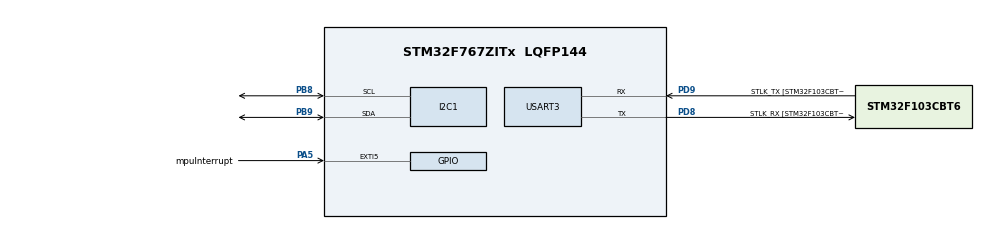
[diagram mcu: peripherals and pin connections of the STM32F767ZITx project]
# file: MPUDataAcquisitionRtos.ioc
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FREERTOS.Queues01=rxQueue,5,uint8_t,0,Static,rxQueueBuffer,rxQueueControlBlock;txQueue,13,uint16_t,0,Static,myQueue02Buffer,myQueue02ControlBlock
FREERTOS.Tasks01=mainTask,24,128,StartDefaultTask,Default,NULL,Static,mainTaskBuffer,mainTaskControlBlock;mpuTask,24,128,StartTask02,Default,NULL,Static,mpuTaskBuffer,mpuTaskControlBlock
I2C1.Analog_Filter=I2C_ANALOGFILTER_DISABLE
I2C1.Timing=0x00B0DBFF
Mcu.Family=STM32F7
Mcu.Name=STM32F767ZITx
Mcu.Package=LQFP144
NVIC.EXTI9_5_IRQn=true\:5\:0\:false\:false\:true\:true\:true\:true
NVIC.PriorityGroup=NVIC_PRIORITYGROUP_4
NVIC.TIM7_IRQn=true\:0\:0\:false\:false\:true\:false\:false\:true
NVIC.TimeBase=TIM7_IRQn
NVIC.TimeBaseIP=TIM7
NVIC.USART3_IRQn=true\:5\:0\:false\:false\:true\:true\:true\:true
PA13.GPIO_Label=TMS
PA13.Mode=Serial_Wire
PA13.Signal=SYS_JTMS-SWDIO
PA14.GPIO_Label=TCK
PA14.Mode=Serial_Wire
PA14.Signal=SYS_JTCK-SWCLK
PA5.GPIO_Label=mpuInterrupt
PA5.Signal=GPXTI5
PB8.Mode=I2C
PB8.Signal=I2C1_SCL
PB9.Mode=I2C
PB9.Signal=I2C1_SDA
PC14/OSC32_IN.Mode=LSE-External-Oscillator
PC14/OSC32_IN.Signal=RCC_OSC32_IN
PC15/OSC32_OUT.Mode=LSE-External-Oscillator
PC15/OSC32_OUT.Signal=RCC_OSC32_OUT
PD8.GPIO_Label=STLK_RX [STM32F103CBT6_PA3]
PD8.Mode=Asynchronous
PD8.Signal=USART3_TX
PD9.GPIO_Label=STLK_TX [STM32F103CBT6_PA2]
PD9.Mode=Asynchronous
PD9.Signal=USART3_RX
PH0/OSC_IN.GPIO_Label=MCO [STM32F103CBT6_PA8]
PH0/OSC_IN.Mode=HSE-External-Clock-Source
PH0/OSC_IN.Signal=RCC_OSC_IN
PH1/OSC_OUT.Mode=HSE-External-Clock-Source
PH1/OSC_OUT.Signal=RCC_OSC_OUT
ProjectManager.HeapSize=0x200
ProjectManager.StackSize=0x400
ProjectManager.TargetToolchain=STM32CubeIDE
RCC.48MHZClocksFreq_Value=24000000
RCC.AHBFreq_Value=96000000
RCC.APB1CLKDivider=RCC_HCLK_DIV2
RCC.APB1Freq_Value=48000000
RCC.APB1TimFreq_Value=96000000
RCC.APB2Freq_Value=96000000
RCC.APB2TimFreq_Value=96000000
RCC.CortexFreq_Value=96000000
RCC.HCLKFreq_Value=96000000
RCC.HSE_VALUE=8000000
RCC.HSI_VALUE=16000000
RCC.PLLM=4
RCC.PLLMUL=RCC_PLL_MUL9
RCC.PLLN=96
RCC.PLLQ=4
RCC.PLLSourceVirtual=RCC_PLLSOURCE_HSE
RCC.PRESCALERUSB=RCC_USBCLKSOURCE_PLL_DIV1_5
RCC.SYSCLKFreq_VALUE=96000000
RCC.SYSCLKSource=RCC_SYSCLKSOURCE_PLLCLK
RCC.SYSCLKSourceVirtual=RCC_SYSCLKSOURCE_PLLCLK
RCC.USBFreq_Value=48000000
RCC.VCOOutputFreq_Value=192000000
USART3.VirtualMode-Asynchronous=VM_ASYNC
VP_FREERTOS_VS_CMSIS_V2.Mode=CMSIS_V2
VP_SYS_VS_tim7.Mode=TIM7
board=NUCLEO-F767ZI

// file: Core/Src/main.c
/* USER CODE BEGIN Header */
/**
  ******************************************************************************
  * @file           : main.c
  * @brief          : Main program body
  ******************************************************************************
  * @attention
  *
  * <h2><center>&copy; Copyright (c) 2020 STMicroelectronics.
  * All rights reserved.</center></h2>
  *
  * This software component is licensed by ST under BSD 3-Clause license,
  * the "License"; You may not use this file except in compliance with the
  * License. You may obtain a copy of the License at:
  *                        opensource.org/licenses/BSD-3-Clause
  *
  ******************************************************************************
  */
/* USER CODE END Header */

#include "main.h"
#include "cmsis_os.h"
#include "i2c.h"
#include "usart.h"
#include "gpio.h"

void SystemClock_Config(void);
void MX_FREERTOS_Init(void);

int main(void)
{

  /* MCU Configuration--------------------------------------------------------*/

  /* Reset of all peripherals, Initializes the Flash interface and the Systick. */
  HAL_Init();

  /* Configure the system clock */
  SystemClock_Config();

  /* Initialize all configured peripherals */
  MX_GPIO_Init();
  MX_USART3_UART_Init();
  MX_I2C1_Init();

  /* Init scheduler */
  osKernelInitialize();  /* Call init function for freertos objects (in freertos.c) */
  MX_FREERTOS_Init();
  /* Start scheduler */
  osKernelStart();

  /* We should never get here as control is now taken by the scheduler */
  /* Infinite loop */
  while (1)
  {

  }
}

void SystemClock_Config(void)
{
  LL_FLASH_SetLatency(LL_FLASH_LATENCY_3);

  if(LL_FLASH_GetLatency() != LL_FLASH_LATENCY_3)
  {
  Error_Handler();
  }
  LL_PWR_SetRegulVoltageScaling(LL_PWR_REGU_VOLTAGE_SCALE3);
  LL_PWR_EnableOverDriveMode();
  LL_RCC_HSE_EnableBypass();
  LL_RCC_HSE_Enable();

   /* Wait till HSE is ready */
  while(LL_RCC_HSE_IsReady() != 1)
  {

  }
  LL_RCC_PLL_ConfigDomain_SYS(LL_RCC_PLLSOURCE_HSE, LL_RCC_PLLM_DIV_4, 96, LL_RCC_PLLP_DIV_2);
  LL_RCC_PLL_Enable();

   /* Wait till PLL is ready */
  while(LL_RCC_PLL_IsReady() != 1)
  {

  }
  LL_RCC_SetAHBPrescaler(LL_RCC_SYSCLK_DIV_1);
  LL_RCC_SetAPB1Prescaler(LL_RCC_APB1_DIV_2);
  LL_RCC_SetAPB2Prescaler(LL_RCC_APB2_DIV_1);
  LL_RCC_SetSysClkSource(LL_RCC_SYS_CLKSOURCE_PLL);

   /* Wait till System clock is ready */
  while(LL_RCC_GetSysClkSource() != LL_RCC_SYS_CLKSOURCE_STATUS_PLL)
  {

  }
  LL_SetSystemCoreClock(96000000);

   /* Update the time base */
  if (HAL_InitTick (TICK_INT_PRIORITY) != HAL_OK)
  {
    Error_Handler();
  };
  LL_RCC_SetUSARTClockSource(LL_RCC_USART3_CLKSOURCE_PCLK1);
  LL_RCC_SetI2CClockSource(LL_RCC_I2C1_CLKSOURCE_PCLK1);
}

 /**
  * @brief  Period elapsed callback in non blocking mode
  * @note   This function is called  when TIM7 interrupt took place, inside
  * HAL_TIM_IRQHandler(). It makes a direct call to HAL_IncTick() to increment
  * a global variable "uwTick" used as application time base.
  * @param  htim : TIM handle
  * @retval None
  */
void HAL_TIM_PeriodElapsedCallback(TIM_HandleTypeDef *htim)
{
  if (htim->Instance == TIM7) {
    HAL_IncTick();
  }
}

void Error_Handler(void)
{
}

/************************ (C) COPYRIGHT STMicroelectronics *****END OF FILE****/

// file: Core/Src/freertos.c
/* USER CODE BEGIN Header */
/**
  ******************************************************************************
  * File Name          : freertos.c
  * Description        : Code for freertos applications
  ******************************************************************************
  * @attention
  *
  * <h2><center>&copy; Copyright (c) 2020 STMicroelectronics.
  * All rights reserved.</center></h2>
  *
  * This software component is licensed by ST under Ultimate Liberty license
  * SLA0044, the "License"; You may not use this file except in compliance with
  * the License. You may obtain a copy of the License at:
  *                             www.st.com/SLA0044
  *
  ******************************************************************************
  */
/* USER CODE END Header */

#include "FreeRTOS.h"
#include "task.h"
#include "main.h"
#include "cmsis_os.h"

typedef StaticTask_t osStaticThreadDef_t;
typedef StaticQueue_t osStaticMessageQDef_t;

/* Definitions for mainTask */
osThreadId_t mainTaskHandle;
uint32_t mainTaskBuffer[ 128 ];
osStaticThreadDef_t mainTaskControlBlock;
const osThreadAttr_t mainTask_attributes = {
  .name = "mainTask",
  .stack_mem = &mainTaskBuffer[0],
  .stack_size = sizeof(mainTaskBuffer),
  .cb_mem = &mainTaskControlBlock,
  .cb_size = sizeof(mainTaskControlBlock),
  .priority = (osPriority_t) osPriorityNormal,
};
/* Definitions for mpuTask */
osThreadId_t mpuTaskHandle;
uint32_t mpuTaskBuffer[ 128 ];
osStaticThreadDef_t mpuTaskControlBlock;
const osThreadAttr_t mpuTask_attributes = {
  .name = "mpuTask",
  .stack_mem = &mpuTaskBuffer[0],
  .stack_size = sizeof(mpuTaskBuffer),
  .cb_mem = &mpuTaskControlBlock,
  .cb_size = sizeof(mpuTaskControlBlock),
  .priority = (osPriority_t) osPriorityNormal,
};
/* Definitions for rxQueue */
osMessageQueueId_t rxQueueHandle;
uint8_t rxQueueBuffer[ 5 * sizeof( uint8_t ) ];
osStaticMessageQDef_t rxQueueControlBlock;
const osMessageQueueAttr_t rxQueue_attributes = {
  .name = "rxQueue",
  .cb_mem = &rxQueueControlBlock,
  .cb_size = sizeof(rxQueueControlBlock),
  .mq_mem = &rxQueueBuffer,
  .mq_size = sizeof(rxQueueBuffer)
};
/* Definitions for txQueue */
osMessageQueueId_t txQueueHandle;
uint8_t myQueue02Buffer[ 13 * sizeof( uint16_t ) ];
osStaticMessageQDef_t myQueue02ControlBlock;
const osMessageQueueAttr_t txQueue_attributes = {
  .name = "txQueue",
  .cb_mem = &myQueue02ControlBlock,
  .cb_size = sizeof(myQueue02ControlBlock),
  .mq_mem = &myQueue02Buffer,
  .mq_size = sizeof(myQueue02Buffer)
};

void StartDefaultTask(void *argument);
void StartMpuTask(void *argument);

void MX_FREERTOS_Init(void); /* (MISRA C 2004 rule 8.1) */

void MX_FREERTOS_Init(void) {

  /* Create the queue(s) */
  /* creation of rxQueue */
  rxQueueHandle = osMessageQueueNew (5, sizeof(uint8_t), &rxQueue_attributes);

  /* creation of txQueue */
  txQueueHandle = osMessageQueueNew (13, sizeof(uint16_t), &txQueue_attributes);

  /* Create the thread(s) */
  /* creation of mainTask */
  mainTaskHandle = osThreadNew(StartDefaultTask, NULL, &mainTask_attributes);

  /* creation of mpuTask */
  mpuTaskHandle = osThreadNew(StartMpuTask, NULL, &mpuTask_attributes);

}

void StartDefaultTask(void *argument)
{
  /* USER CODE BEGIN StartDefaultTask */
  /* Infinite loop */
  for(;;)
  {

	  // leggo i comandi da seriale

	  // eseguo i comandi (avvio o fermo l'acquisizione dall'mpu)
  }
  /* USER CODE END StartDefaultTask */
}

void StartMpuTask(void *argument)
{
  /* USER CODE BEGIN StartMpuTask */
  /* Infinite loop */
  for(;;)
  {
	  // se sono qua è perché è scattato l'interrupt dell'mpu
	  // acquisisco i dati dall'mpu
	  // invio i dati alla seriale
  }
  /* USER CODE END StartMpuTask */
}

/************************ (C) COPYRIGHT STMicroelectronics *****END OF FILE****/
